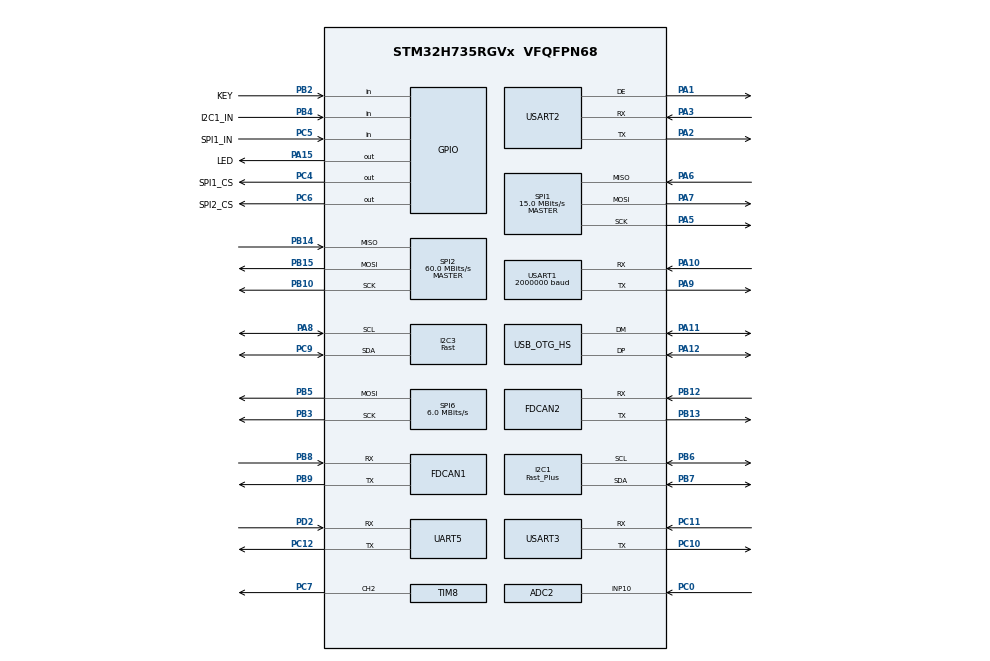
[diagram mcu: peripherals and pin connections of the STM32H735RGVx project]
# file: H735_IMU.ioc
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ADC2.Channel-0\#ChannelRegularConversion=ADC_CHANNEL_10
ADC2.NbrOfConversionFlag=1
ADC2.OffsetNumber-0\#ChannelRegularConversion=ADC_OFFSET_NONE
ADC2.OffsetSignedSaturation-0\#ChannelRegularConversion=DISABLE
ADC2.Rank-0\#ChannelRegularConversion=1
ADC2.SamplingTime-0\#ChannelRegularConversion=ADC_SAMPLETIME_1CYCLE_5
Bdma.Request0=SPI6_TX
Bdma.RequestsNb=1
Bdma.SPI6_TX.0.Direction=DMA_MEMORY_TO_PERIPH
Bdma.SPI6_TX.0.EventEnable=DISABLE
Bdma.SPI6_TX.0.Instance=BDMA_Channel0
Bdma.SPI6_TX.0.MemDataAlignment=DMA_MDATAALIGN_BYTE
Bdma.SPI6_TX.0.MemInc=DMA_MINC_ENABLE
Bdma.SPI6_TX.0.Mode=DMA_NORMAL
Bdma.SPI6_TX.0.PeriphDataAlignment=DMA_PDATAALIGN_BYTE
Bdma.SPI6_TX.0.PeriphInc=DMA_PINC_DISABLE
Bdma.SPI6_TX.0.Polarity=HAL_DMAMUX_REQ_GEN_RISING
Bdma.SPI6_TX.0.Priority=DMA_PRIORITY_LOW
Bdma.SPI6_TX.0.RequestNumber=1
Bdma.SPI6_TX.0.SignalID=NONE
Bdma.SPI6_TX.0.SyncEnable=DISABLE
Bdma.SPI6_TX.0.SyncPolarity=HAL_DMAMUX_SYNC_NO_EVENT
Bdma.SPI6_TX.0.SyncRequestNumber=1
Bdma.SPI6_TX.0.SyncSignalID=NONE
CORTEX_M7.CPU_ICache=Enabled
CORTEX_M7.MPU_Control=MPU_PRIVILEGED_DEFAULT
CORTEX_M7.default_mode_Activation=1
Dma.Request0=USART1_RX
Dma.Request1=USART1_TX
Dma.USART1_RX.0.Direction=DMA_PERIPH_TO_MEMORY
Dma.USART1_RX.0.EventEnable=DISABLE
Dma.USART1_RX.0.FIFOMode=DMA_FIFOMODE_DISABLE
Dma.USART1_RX.0.Instance=DMA1_Stream0
Dma.USART1_RX.0.MemDataAlignment=DMA_MDATAALIGN_BYTE
Dma.USART1_RX.0.MemInc=DMA_MINC_ENABLE
Dma.USART1_RX.0.Mode=DMA_NORMAL
Dma.USART1_RX.0.PeriphDataAlignment=DMA_PDATAALIGN_BYTE
Dma.USART1_RX.0.PeriphInc=DMA_PINC_DISABLE
Dma.USART1_RX.0.Polarity=HAL_DMAMUX_REQ_GEN_RISING
Dma.USART1_RX.0.Priority=DMA_PRIORITY_LOW
Dma.USART1_RX.0.RequestNumber=1
Dma.USART1_RX.0.SignalID=NONE
Dma.USART1_RX.0.SyncEnable=DISABLE
Dma.USART1_RX.0.SyncPolarity=HAL_DMAMUX_SYNC_NO_EVENT
Dma.USART1_RX.0.SyncRequestNumber=1
Dma.USART1_RX.0.SyncSignalID=NONE
Dma.USART1_TX.1.Direction=DMA_MEMORY_TO_PERIPH
Dma.USART1_TX.1.EventEnable=DISABLE
Dma.USART1_TX.1.FIFOMode=DMA_FIFOMODE_DISABLE
Dma.USART1_TX.1.Instance=DMA1_Stream1
Dma.USART1_TX.1.MemDataAlignment=DMA_MDATAALIGN_BYTE
Dma.USART1_TX.1.MemInc=DMA_MINC_ENABLE
Dma.USART1_TX.1.Mode=DMA_NORMAL
Dma.USART1_TX.1.PeriphDataAlignment=DMA_PDATAALIGN_BYTE
Dma.USART1_TX.1.PeriphInc=DMA_PINC_DISABLE
Dma.USART1_TX.1.Polarity=HAL_DMAMUX_REQ_GEN_RISING
Dma.USART1_TX.1.Priority=DMA_PRIORITY_LOW
Dma.USART1_TX.1.RequestNumber=1
Dma.USART1_TX.1.SignalID=NONE
Dma.USART1_TX.1.SyncEnable=DISABLE
Dma.USART1_TX.1.SyncPolarity=HAL_DMAMUX_SYNC_NO_EVENT
Dma.USART1_TX.1.SyncRequestNumber=1
Dma.USART1_TX.1.SyncSignalID=NONE
FDCAN1.CalculateBaudRateNominal=2000000
FDCAN1.CalculateTimeBitNominal=500
FDCAN1.CalculateTimeQuantumNominal=166.66666666666666
FDCAN2.CalculateBaudRateNominal=2000000
FDCAN2.CalculateTimeBitNominal=500
FDCAN2.CalculateTimeQuantumNominal=166.66666666666666
I2C1.I2C_Speed_Mode=I2C_Fast_Plus
I2C1.Timing=0x0050174F
I2C3.I2C_Speed_Mode=I2C_Fast
I2C3.Timing=0x00B03FDB
Mcu.Family=STM32H7
Mcu.Name=STM32H735RGVx
Mcu.Package=VFQFPN68
NVIC.BDMA_Channel0_IRQn=true\:0\:0\:false\:false\:true\:false\:true\:true
NVIC.DMA1_Stream0_IRQn=true\:0\:0\:false\:false\:true\:false\:true\:true
NVIC.DMA1_Stream1_IRQn=true\:0\:0\:false\:false\:true\:false\:true\:true
NVIC.OTG_HS_IRQn=true\:0\:0\:false\:false\:true\:false\:true\:true
NVIC.PriorityGroup=NVIC_PRIORITYGROUP_4
NVIC.SPI6_IRQn=true\:0\:0\:false\:false\:true\:false\:true\:true
NVIC.TIM6_DAC_IRQn=true\:0\:0\:false\:false\:true\:true\:true\:true
NVIC.TIM8_TRG_COM_TIM14_IRQn=true\:15\:0\:false\:false\:true\:false\:true\:true
NVIC.TimeBase=TIM8_TRG_COM_TIM14_IRQn
NVIC.TimeBaseIP=TIM14
NVIC.USART1_IRQn=true\:0\:0\:false\:false\:true\:true\:true\:true
PA1.Mode=Hardware Flow Control (RS485)
PA1.Signal=USART2_DE
PA10.GPIO_Speed=GPIO_SPEED_FREQ_VERY_HIGH
PA10.Mode=Asynchronous
PA10.Signal=USART1_RX
PA11.Mode=Device_Only_FS
PA11.Signal=USB_OTG_HS_DM
PA12.Mode=Device_Only_FS
PA12.Signal=USB_OTG_HS_DP
PA13(JTMS/SWDIO).Mode=Serial_Wire
PA13(JTMS/SWDIO).Signal=DEBUG_JTMS-SWDIO
PA14(JTCK/SWCLK).Mode=Serial_Wire
PA14(JTCK/SWCLK).Signal=DEBUG_JTCK-SWCLK
PA15(JTDI).GPIO_Label=LED
PA15(JTDI).Signal=GPIO_Output
PA2.Mode=Asynchronous
PA2.Signal=USART2_TX
PA3.Mode=Asynchronous
PA3.Signal=USART2_RX
PA5.GPIO_Speed=GPIO_SPEED_FREQ_HIGH
PA5.Mode=Full_Duplex_Master
PA5.Signal=SPI1_SCK
PA6.GPIO_Speed=GPIO_SPEED_FREQ_HIGH
PA6.Mode=Full_Duplex_Master
PA6.Signal=SPI1_MISO
PA7.GPIO_Speed=GPIO_SPEED_FREQ_HIGH
PA7.Mode=Full_Duplex_Master
PA7.Signal=SPI1_MOSI
PA8.Mode=I2C
PA8.Signal=I2C3_SCL
PA9.GPIO_Speed=GPIO_SPEED_FREQ_VERY_HIGH
PA9.Mode=Asynchronous
PA9.Signal=USART1_TX
PB10.GPIO_Speed=GPIO_SPEED_FREQ_VERY_HIGH
PB10.Mode=Full_Duplex_Master
PB10.Signal=SPI2_SCK
PB12.Mode=FDCAN_Activate
PB12.Signal=FDCAN2_RX
PB13.Mode=FDCAN_Activate
PB13.Signal=FDCAN2_TX
PB14.GPIO_Speed=GPIO_SPEED_FREQ_VERY_HIGH
PB14.Mode=Full_Duplex_Master
PB14.Signal=SPI2_MISO
PB15.GPIO_Speed=GPIO_SPEED_FREQ_VERY_HIGH
PB15.Mode=Full_Duplex_Master
PB15.Signal=SPI2_MOSI
PB2.GPIO_Label=KEY
PB2.Signal=GPIO_Input
PB3(JTDO/TRACESWO).GPIO_Speed=GPIO_SPEED_FREQ_MEDIUM
PB3(JTDO/TRACESWO).Mode=TX_Only_Simplex_Unidirect_Master
PB3(JTDO/TRACESWO).Signal=SPI6_SCK
PB4(NJTRST).GPIO_Label=I2C1_IN
PB4(NJTRST).Signal=GPIO_Input
PB5.GPIO_Speed=GPIO_SPEED_FREQ_MEDIUM
PB5.Mode=TX_Only_Simplex_Unidirect_Master
PB5.Signal=SPI6_MOSI
PB6.Mode=I2C
PB6.Signal=I2C1_SCL
PB7.Mode=I2C
PB7.Signal=I2C1_SDA
PB8.Mode=FDCAN_Activate
PB8.Signal=FDCAN1_RX
PB9.Mode=FDCAN_Activate
PB9.Signal=FDCAN1_TX
PC0.Signal=ADCx_INP10
PC10.Mode=Asynchronous
PC10.Signal=USART3_TX
PC11.Mode=Asynchronous
PC11.Signal=USART3_RX
PC12.Mode=Asynchronous
PC12.Signal=UART5_TX
PC14-OSC32_IN.Mode=LSE-External-Oscillator
PC14-OSC32_IN.Signal=RCC_OSC32_IN
PC15-OSC32_OUT.Mode=LSE-External-Oscillator
PC15-OSC32_OUT.Signal=RCC_OSC32_OUT
PC4.GPIO_Label=SPI1_CS
PC4.GPIO_Speed=GPIO_SPEED_FREQ_HIGH
PC4.PinState=GPIO_PIN_SET
PC4.Signal=GPIO_Output
PC5.GPIO_Label=SPI1_IN
PC5.Signal=GPIO_Input
PC6.GPIO_Label=SPI2_CS
PC6.GPIO_Speed=GPIO_SPEED_FREQ_VERY_HIGH
PC6.PinState=GPIO_PIN_SET
PC6.Signal=GPIO_Output
PC7.Signal=S_TIM8_CH2
PC9.Mode=I2C
PC9.Signal=I2C3_SDA
PD2.Mode=Asynchronous
PD2.Signal=UART5_RX
PH0-OSC_IN.Mode=HSE-External-Oscillator
PH0-OSC_IN.Signal=RCC_OSC_IN
PH1-OSC_OUT.Mode=HSE-External-Oscillator
PH1-OSC_OUT.Signal=RCC_OSC_OUT
ProjectManager.HeapSize=0x400
ProjectManager.StackSize=0x800
ProjectManager.TargetToolchain=CMake
RCC.ADCFreq_Value=96000000
RCC.APB1Freq_Value=120000000
RCC.APB2Freq_Value=120000000
RCC.APB3Freq_Value=120000000
RCC.APB4Freq_Value=120000000
RCC.CortexFreq_Value=480000000
RCC.D1PPRE=RCC_APB3_DIV2
RCC.D2PPRE1=RCC_APB1_DIV2
RCC.D2PPRE2=RCC_APB2_DIV2
RCC.D3PPRE=RCC_APB4_DIV2
RCC.DIVM1=1
RCC.DIVM2=1
RCC.DIVM3=1
RCC.DIVN1=30
RCC.DIVN2=12
RCC.DIVN3=12
RCC.DIVP1=1
RCC.DIVQ1=4
RCC.DIVQ3=4
RCC.DIVR1=4
RCC.EnbaleCSS=false
RCC.FDCANCLockSelection=RCC_FDCANCLKSOURCE_PLL2
RCC.HCLKFreq_Value=240000000
RCC.HPRE=RCC_HCLK_DIV2
RCC.HSE_VALUE=16000000
RCC.PLL1_VCO_SEL-AdvancedSettings=RCC_PLL1VCOMEDIUM
RCC.PLL2FRACN=0
RCC.PLL3FRACN=0
RCC.PLLFRACN=0
RCC.PLLSourceVirtual=RCC_PLLSOURCE_HSE
RCC.SPI6CLockSelection=RCC_SPI6CLKSOURCE_PLL2
RCC.SYSCLKFreq_VALUE=480000000
RCC.SYSCLKSource=RCC_SYSCLKSOURCE_PLLCLK
RCC.USBCLockSelection=RCC_USBCLKSOURCE_PLL3
RCC.USBFreq_Value=48000000
SH.ADCx_INP10.0=ADC2_INP10,IN10-Single-Ended
SH.S_TIM8_CH2.0=TIM8_CH2,PWM Generation2 CH2
SPI1.BaudRatePrescaler=SPI_BAUDRATEPRESCALER_8
SPI1.CalculateBaudRate=15.0 MBits/s
SPI1.DataSize=SPI_DATASIZE_8BIT
SPI1.Direction=SPI_DIRECTION_2LINES
SPI1.MasterKeepIOState=SPI_MASTER_KEEP_IO_STATE_ENABLE
SPI1.Mode=SPI_MODE_MASTER
SPI1.VirtualType=VM_MASTER
SPI2.BaudRatePrescaler=SPI_BAUDRATEPRESCALER_2
SPI2.CLKPhase=SPI_PHASE_1EDGE
SPI2.CalculateBaudRate=60.0 MBits/s
SPI2.DataSize=SPI_DATASIZE_8BIT
SPI2.Direction=SPI_DIRECTION_2LINES
SPI2.MasterKeepIOState=SPI_MASTER_KEEP_IO_STATE_ENABLE
SPI2.Mode=SPI_MODE_MASTER
SPI2.VirtualType=VM_MASTER
SPI6.BaudRatePrescaler=SPI_BAUDRATEPRESCALER_16
SPI6.CalculateBaudRate=6.0 MBits/s
SPI6.DataSize=SPI_DATASIZE_8BIT
SPI6.Direction=SPI_DIRECTION_2LINES_TXONLY
SPI6.Mode=SPI_MODE_MASTER
SPI6.VirtualType=VM_MASTER
TIM6.Period=5000 - 1
TIM6.Prescaler=240 - 1
TIM7.Prescaler=240 - 1
TIM8.Channel-PWM\ Generation2\ CH2=TIM_CHANNEL_2
TIM8.Period=1000 - 1
TIM8.Prescaler=240 - 1
USART1.BaudRate=2000000
USART1.VirtualMode-Asynchronous=VM_ASYNC
USART2.VirtualMode-Asynchronous=VM_ASYNC
USART2.VirtualMode-Hardware\ Flow\ Control\ (RS485)=VM_ASYNC
USART3.VirtualMode-Asynchronous=VM_ASYNC
USB_DEVICE.CLASS_NAME_HS=CDC
USB_DEVICE.VirtualMode=Cdc
USB_DEVICE.VirtualModeHS=Cdc_HS
USB_OTG_HS.VirtualMode=Device_Only_FS
VP_MEMORYMAP_VS_MEMORYMAP.Mode=CurAppReg
VP_SYS_VS_tim14.Mode=TIM14
VP_TIM6_VS_ClockSourceINT.Mode=Enable_Timer
VP_TIM7_VS_ClockSourceINT.Mode=Enable_Timer
VP_TIM8_VS_ClockSourceINT.Mode=Internal
VP_USB_DEVICE_VS_USB_DEVICE_CDC_HS.Mode=CDC_HS
board=custom

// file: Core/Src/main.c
/* USER CODE BEGIN Header */
/**
  ******************************************************************************
  * @file           : main.c
  * @brief          : Main program body
  ******************************************************************************
  * @attention
  *
  * Copyright (c) 2026 STMicroelectronics.
  * All rights reserved.
  *
  * This software is licensed under terms that can be found in the LICENSE file
  * in the root directory of this software component.
  * If no LICENSE file comes with this software, it is provided AS-IS.
  *
  ******************************************************************************
  */
/* USER CODE END Header */
#include "main.h"
#include "adc.h"
#include "bdma.h"
#include "dma.h"
#include "fdcan.h"
#include "i2c.h"
#include "spi.h"
#include "tim.h"
#include "usart.h"
#include "usb_device.h"
#include "gpio.h"

/* USER CODE BEGIN Includes */
#include "app_sys.h"
#include "app_imu.h"

/* USER CODE END Includes */

void SystemClock_Config(void);
void PeriphCommonClock_Config(void);
static void MPU_Config(void);

int main(void)
{

  /* MPU Configuration--------------------------------------------------------*/
  MPU_Config();

  /* Enable the CPU Cache */

  /* Enable I-Cache---------------------------------------------------------*/
  SCB_EnableICache();

  /* MCU Configuration--------------------------------------------------------*/

  /* Reset of all peripherals, Initializes the Flash interface and the Systick. */
  HAL_Init();

  /* USER CODE BEGIN Init */
  HAL_RCC_DeInit();

  /* USER CODE END Init */

  /* Configure the system clock */
  SystemClock_Config();

  /* Configure the peripherals common clocks */
  PeriphCommonClock_Config();

  /* Initialize all configured peripherals */
  MX_GPIO_Init();
  MX_DMA_Init();
  MX_BDMA_Init();
  MX_ADC2_Init();
  MX_FDCAN1_Init();
  MX_FDCAN2_Init();
  MX_I2C1_Init();
  MX_I2C3_Init();
  MX_SPI1_Init();
  MX_SPI2_Init();
  MX_SPI6_Init();
  MX_TIM8_Init();
  MX_UART5_Init();
  MX_USART1_UART_Init();
  MX_USART2_UART_Init();
  MX_USART3_UART_Init();
  MX_USB_DEVICE_Init();
  MX_TIM6_Init();
  MX_TIM7_Init();
  /* USER CODE BEGIN 2 */
  sys_main_init();

  /* USER CODE END 2 */

  /* Infinite loop */
  /* USER CODE BEGIN WHILE */
  while (1)
  {
    sys_main_while();
    /* USER CODE END WHILE */

  }
}

void SystemClock_Config(void)
{
  RCC_OscInitTypeDef RCC_OscInitStruct = {0};
  RCC_ClkInitTypeDef RCC_ClkInitStruct = {0};

  /** Supply configuration update enable
  */
  HAL_PWREx_ConfigSupply(PWR_DIRECT_SMPS_SUPPLY);

  /** Configure the main internal regulator output voltage
  */
  __HAL_PWR_VOLTAGESCALING_CONFIG(PWR_REGULATOR_VOLTAGE_SCALE0);

  while(!__HAL_PWR_GET_FLAG(PWR_FLAG_VOSRDY)) {}

  /** Initializes the RCC Oscillators according to the specified parameters
  * in the RCC_OscInitTypeDef structure.
  */
  RCC_OscInitStruct.OscillatorType = RCC_OSCILLATORTYPE_HSE;
  RCC_OscInitStruct.HSEState = RCC_HSE_ON;
  RCC_OscInitStruct.PLL.PLLState = RCC_PLL_ON;
  RCC_OscInitStruct.PLL.PLLSource = RCC_PLLSOURCE_HSE;
  RCC_OscInitStruct.PLL.PLLM = 1;
  RCC_OscInitStruct.PLL.PLLN = 30;
  RCC_OscInitStruct.PLL.PLLP = 1;
  RCC_OscInitStruct.PLL.PLLQ = 4;
  RCC_OscInitStruct.PLL.PLLR = 4;
  RCC_OscInitStruct.PLL.PLLRGE = RCC_PLL1VCIRANGE_3;
  RCC_OscInitStruct.PLL.PLLVCOSEL = RCC_PLL1VCOWIDE;
  RCC_OscInitStruct.PLL.PLLFRACN = 0;
  if (HAL_RCC_OscConfig(&RCC_OscInitStruct) != HAL_OK)
  {
    Error_Handler();
  }

  /** Initializes the CPU, AHB and APB buses clocks
  */
  RCC_ClkInitStruct.ClockType = RCC_CLOCKTYPE_HCLK|RCC_CLOCKTYPE_SYSCLK
                              |RCC_CLOCKTYPE_PCLK1|RCC_CLOCKTYPE_PCLK2
                              |RCC_CLOCKTYPE_D3PCLK1|RCC_CLOCKTYPE_D1PCLK1;
  RCC_ClkInitStruct.SYSCLKSource = RCC_SYSCLKSOURCE_PLLCLK;
  RCC_ClkInitStruct.SYSCLKDivider = RCC_SYSCLK_DIV1;
  RCC_ClkInitStruct.AHBCLKDivider = RCC_HCLK_DIV2;
  RCC_ClkInitStruct.APB3CLKDivider = RCC_APB3_DIV2;
  RCC_ClkInitStruct.APB1CLKDivider = RCC_APB1_DIV2;
  RCC_ClkInitStruct.APB2CLKDivider = RCC_APB2_DIV2;
  RCC_ClkInitStruct.APB4CLKDivider = RCC_APB4_DIV2;

  if (HAL_RCC_ClockConfig(&RCC_ClkInitStruct, FLASH_LATENCY_3) != HAL_OK)
  {
    Error_Handler();
  }
}

void PeriphCommonClock_Config(void)
{
  RCC_PeriphCLKInitTypeDef PeriphClkInitStruct = {0};

  /** Initializes the peripherals clock
  */
  PeriphClkInitStruct.PeriphClockSelection = RCC_PERIPHCLK_SPI6|RCC_PERIPHCLK_ADC
                              |RCC_PERIPHCLK_FDCAN;
  PeriphClkInitStruct.PLL2.PLL2M = 1;
  PeriphClkInitStruct.PLL2.PLL2N = 12;
  PeriphClkInitStruct.PLL2.PLL2P = 2;
  PeriphClkInitStruct.PLL2.PLL2Q = 2;
  PeriphClkInitStruct.PLL2.PLL2R = 2;
  PeriphClkInitStruct.PLL2.PLL2RGE = RCC_PLL2VCIRANGE_3;
  PeriphClkInitStruct.PLL2.PLL2VCOSEL = RCC_PLL2VCOWIDE;
  PeriphClkInitStruct.PLL2.PLL2FRACN = 0;
  PeriphClkInitStruct.FdcanClockSelection = RCC_FDCANCLKSOURCE_PLL2;
  PeriphClkInitStruct.AdcClockSelection = RCC_ADCCLKSOURCE_PLL2;
  PeriphClkInitStruct.Spi6ClockSelection = RCC_SPI6CLKSOURCE_PLL2;
  if (HAL_RCCEx_PeriphCLKConfig(&PeriphClkInitStruct) != HAL_OK)
  {
    Error_Handler();
  }
}

 /* MPU Configuration */

void MPU_Config(void)
{
  MPU_Region_InitTypeDef MPU_InitStruct = {0};

  /* Disables the MPU */
  HAL_MPU_Disable();

  /** Initializes and configures the Region and the memory to be protected
  */
  MPU_InitStruct.Enable = MPU_REGION_ENABLE;
  MPU_InitStruct.Number = MPU_REGION_NUMBER0;
  MPU_InitStruct.BaseAddress = 0x0;
  MPU_InitStruct.Size = MPU_REGION_SIZE_4GB;
  MPU_InitStruct.SubRegionDisable = 0x87;
  MPU_InitStruct.TypeExtField = MPU_TEX_LEVEL0;
  MPU_InitStruct.AccessPermission = MPU_REGION_NO_ACCESS;
  MPU_InitStruct.DisableExec = MPU_INSTRUCTION_ACCESS_DISABLE;
  MPU_InitStruct.IsShareable = MPU_ACCESS_SHAREABLE;
  MPU_InitStruct.IsCacheable = MPU_ACCESS_NOT_CACHEABLE;
  MPU_InitStruct.IsBufferable = MPU_ACCESS_NOT_BUFFERABLE;

  HAL_MPU_ConfigRegion(&MPU_InitStruct);
  /* Enables the MPU */
  HAL_MPU_Enable(MPU_PRIVILEGED_DEFAULT);

}

void HAL_TIM_PeriodElapsedCallback(TIM_HandleTypeDef *htim)
{
  if (htim->Instance == TIM14)
  {
    HAL_IncTick();
  }
  /* USER CODE BEGIN Callback 1 */
  if (htim->Instance == TIM6)
  {
    app_imu_update();
  }
  /* USER CODE END Callback 1 */
}

void Error_Handler(void)
{
  __disable_irq();
  while (1)
  {
  }
}
